VERSION ""

NS_ :

BS_:

BU_:

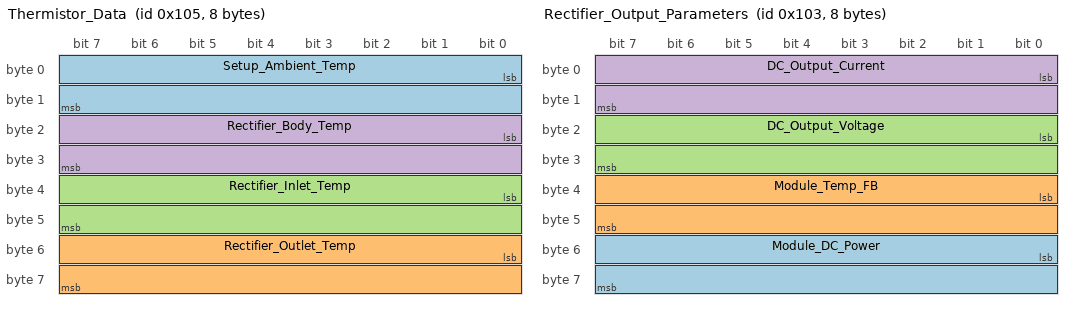
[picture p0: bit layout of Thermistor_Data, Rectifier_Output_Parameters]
BO_ 261 Thermistor_Data: 8 Vector__XXX
 SG_ Setup_Ambient_Temp : 0|16@1+ (0.01,-100) [-100|555.35] "" Vector__XXX
 SG_ Rectifier_Outlet_Temp : 48|16@1+ (0.01,-100) [-100|555.35] "" Vector__XXX
 SG_ Rectifier_Inlet_Temp : 32|16@1+ (0.01,-100) [-100|555.35] "" Vector__XXX
 SG_ Rectifier_Body_Temp : 16|16@1+ (0.01,-100) [-100|555.35] "" Vector__XXX

BO_ 260 Rectifier_Status_Faults: 5 Vector__XXX
 SG_ Total_Current : 24|16@1+ (0.01,0) [0|65535] "" Vector__XXX
 SG_ Warning_Status : 16|1@1+ (1,0) [0|1] "" Vector__XXX
 SG_ Standby_Protection_Status : 6|1@1+ (1,0) [0|1] "" Vector__XXX
 SG_ Running_Status : 7|1@1+ (1,0) [0|1] "" Vector__XXX
 SG_ Radiator_Over_Temprature : 12|1@1+ (1,0) [0|1] "" Vector__XXX
 SG_ PFC_Abnormal : 1|1@1+ (1,0) [0|1] "" Vector__XXX
 SG_ Parallel_Address_Conflict : 8|1@1+ (1,0) [0|1] "" Vector__XXX
 SG_ Output_Short : 13|1@1+ (1,0) [0|1] "" Vector__XXX
 SG_ Output_Over_Voltage : 15|1@1+ (1,0) [0|1] "" Vector__XXX
 SG_ Output_Over_Current : 14|1@1+ (1,0) [0|1] "" Vector__XXX
 SG_ Input_Mode : 4|1@1+ (1,0) [0|1] "" Vector__XXX
 SG_ Inpur_Power_Abnormal : 3|1@1+ (1,0) [0|1] "" Vector__XXX
 SG_ Inpur_Phase_Loss : 2|1@1+ (1,0) [0|1] "" Vector__XXX
 SG_ Fault_Status : 5|1@1+ (1,0) [0|1] "" Vector__XXX
 SG_ Fan_Abnormal : 0|1@1+ (1,0) [0|1] "" Vector__XXX
 SG_ Discharge_Abnormal : 9|1@1+ (1,0) [0|1] "" Vector__XXX
 SG_ Communication_Abnormal : 10|1@1+ (1,0) [0|1] "" Vector__XXX
 SG_ Ambient_Over_Temperature : 11|1@1+ (1,0) [0|1] "" Vector__XXX

BO_ 259 Rectifier_Output_Parameters: 8 Vector__XXX
 SG_ Module_DC_Power : 48|16@1+ (1,0) [0|65535] "" Vector__XXX
 SG_ Module_Temp_FB : 32|16@1+ (0.01,-100) [-100|555.35] "" Vector__XXX
 SG_ DC_Output_Voltage : 16|16@1+ (0.1,0) [0|6553.5] "" Vector__XXX
 SG_ DC_Output_Current : 0|16@1+ (0.01,0) [0|655.35] "" Vector__XXX

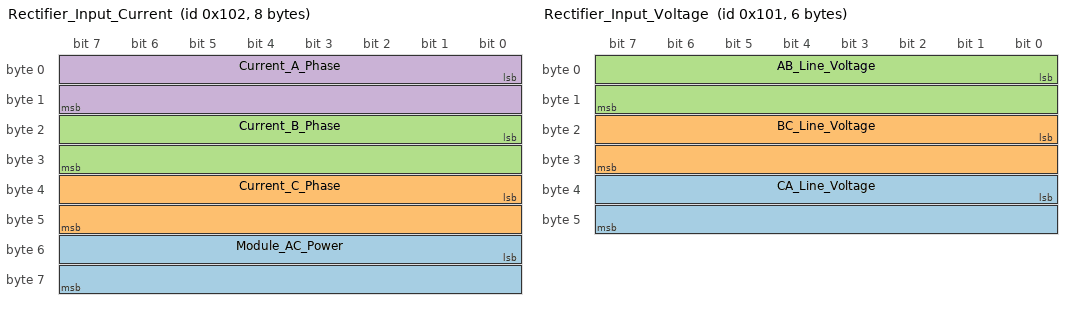
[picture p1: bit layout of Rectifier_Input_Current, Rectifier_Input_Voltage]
BO_ 258 Rectifier_Input_Current: 8 Vector__XXX
 SG_ Module_AC_Power : 48|16@1+ (1,0) [0|65535] "" Vector__XXX
 SG_ Current_C_Phase : 32|16@1+ (0.01,0) [0|655.35] "" Vector__XXX
 SG_ Current_B_Phase : 16|16@1+ (0.01,0) [0|655.35] "" Vector__XXX
 SG_ Current_A_Phase : 0|16@1+ (0.01,0) [0|655.35] "" Vector__XXX

BO_ 257 Rectifier_Input_Voltage: 6 Vector__XXX
 SG_ CA_Line_Voltage : 32|16@1+ (0.01,0) [0|655.35] "" Vector__XXX
 SG_ BC_Line_Voltage : 16|16@1+ (0.01,0) [0|655.35] "" Vector__XXX
 SG_ AB_Line_Voltage : 0|16@1+ (0.01,0) [0|655.35] "" Vector__XXX

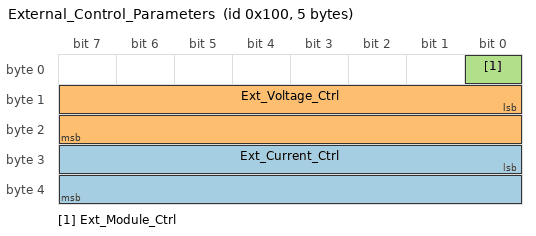
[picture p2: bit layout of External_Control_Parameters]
BO_ 256 External_Control_Parameters: 5 Vector__XXX
 SG_ Ext_Current_Ctrl : 24|16@1+ (0.01,0) [0|655.35] "" Vector__XXX
 SG_ Ext_Voltage_Ctrl : 8|16@1+ (0.1,0) [0|6553.5] "" Vector__XXX
 SG_ Ext_Module_Ctrl : 0|1@1+ (1,0) [0|1] "" Vector__XXX

BA_DEF_  "BusType" STRING ;
BA_DEF_DEF_  "BusType" "CAN";
